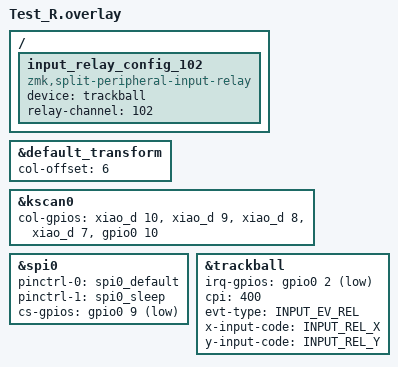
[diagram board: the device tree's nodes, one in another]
#include "Test.dtsi"
#include "Test_trackball.dtsi"

&default_transform {
    col-offset = <6>;
};

&kscan0 {
        col-gpios
            = <&xiao_d 10 GPIO_ACTIVE_HIGH>
            , <&xiao_d 9 GPIO_ACTIVE_HIGH> 
            , <&xiao_d 8 GPIO_ACTIVE_HIGH> 
            , <&xiao_d 7 GPIO_ACTIVE_HIGH> 
            , <&gpio0 10 GPIO_ACTIVE_HIGH>
            ;
};

&spi0 {
    status = "okay";
    pinctrl-0 = <&spi0_default>;
    pinctrl-1 = <&spi0_sleep>;
    pinctrl-names = "default", "sleep";
    cs-gpios = <&gpio0 9 GPIO_ACTIVE_LOW>;
};

&trackball {
    status = "okay";
	irq-gpios = <&gpio0 2 (GPIO_ACTIVE_LOW | GPIO_PULL_UP)>;
	cpi = <400>;
	evt-type = <INPUT_EV_REL>;
	x-input-code = <INPUT_REL_X>;
	y-input-code = <INPUT_REL_Y>;
};

/ {
	/* for peripheral side, define (input-device)-to-(relay-channel) mapping */
	input_relay_config_102 {
		compatible = "zmk,split-peripheral-input-relay";

		/* peripheral side input device, used to be intecepted and be resurrected on central */
		device = <&trackball>;
		
		/* channel id, used to annotate raw input event */
		/* NOTE: should matching relay-channel on central overlay */
		relay-channel = <102>;
	};
};


